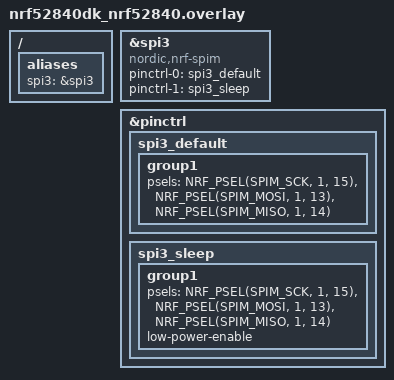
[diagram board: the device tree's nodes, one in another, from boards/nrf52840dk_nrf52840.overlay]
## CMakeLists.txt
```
cmake_minimum_required(VERSION 3.20.0)

find_package(Zephyr REQUIRED HINTS $ENV{ZEPHYR_BASE})
project(biospur_gr_module)

target_sources(app PRIVATE
  src/main.c
  src/ads1298.c
  src/device_id.c
)

target_include_directories(app PRIVATE
  ${CMAKE_CURRENT_SOURCE_DIR}/include
  ${CMAKE_CURRENT_SOURCE_DIR}/../shared/include
)
```

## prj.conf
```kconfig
# GR module: B306 / nRF52840 BLE Peripheral baseline.

CONFIG_MAIN_STACK_SIZE=4096
CONFIG_SYSTEM_WORKQUEUE_STACK_SIZE=2048
CONFIG_HEAP_MEM_POOL_SIZE=8192

CONFIG_PRINTK=y
CONFIG_CONSOLE=y
CONFIG_UART_CONSOLE=n
CONFIG_USE_SEGGER_RTT=y
CONFIG_RTT_CONSOLE=y

CONFIG_BT=y
CONFIG_BT_PERIPHERAL=y
CONFIG_BT_CENTRAL=n
CONFIG_BT_DEVICE_NAME_DYNAMIC=y
CONFIG_BT_MAX_CONN=1
CONFIG_BT_NUS=y
CONFIG_BT_GATT_CLIENT=y
CONFIG_BT_GATT_DM=y

CONFIG_BT_CTLR_PHY_2M=y
CONFIG_BT_USER_PHY_UPDATE=y
CONFIG_BT_CTLR_DATA_LENGTH_MAX=251
CONFIG_BT_L2CAP_TX_MTU=247
CONFIG_BT_BUF_ACL_TX_SIZE=251
CONFIG_BT_BUF_ACL_RX_SIZE=251
CONFIG_BT_BUF_ACL_TX_COUNT=10
CONFIG_BT_BUF_ACL_RX_COUNT=10
CONFIG_BT_CONN_TX_MAX=16

CONFIG_GPIO=y
CONFIG_PINCTRL=y
CONFIG_I2C=y
CONFIG_SPI=y

CONFIG_BOOTLOADER_MCUBOOT=y
CONFIG_MCUBOOT_BOOTUTIL_LIB=y
CONFIG_MCUBOOT_SIGNATURE_KEY_FILE="bootloader/mcuboot/root-ec-p256.pem"
CONFIG_MCUBOOT_IMGTOOL_SIGN_VERSION="0.0.3+0"
CONFIG_FLASH=y
CONFIG_FLASH_PAGE_LAYOUT=y
CONFIG_FLASH_MAP=y
CONFIG_IMG_MANAGER=y
CONFIG_STREAM_FLASH=y

CONFIG_NET_BUF=y
CONFIG_ZCBOR=y
CONFIG_CRC=y
CONFIG_MCUMGR=y
CONFIG_MCUMGR_GRP_IMG=y
CONFIG_MCUMGR_GRP_IMG_VERBOSE_ERR=y
CONFIG_MCUMGR_GRP_IMG_ALLOW_ERASE_PENDING=y
CONFIG_MCUMGR_GRP_OS=y
CONFIG_MCUMGR_GRP_OS_BOOTLOADER_INFO=y
CONFIG_MCUMGR_GRP_OS_MCUMGR_PARAMS=y
CONFIG_MCUMGR_TRANSPORT_BT=y
CONFIG_MCUMGR_TRANSPORT_BT_PERM_RW=y
CONFIG_MCUMGR_TRANSPORT_BT_CONN_PARAM_CONTROL=y
CONFIG_MCUMGR_TRANSPORT_BT_REASSEMBLY=y
CONFIG_MCUMGR_TRANSPORT_NETBUF_SIZE=1536
CONFIG_MCUMGR_TRANSPORT_WORKQUEUE_STACK_SIZE=3072
```

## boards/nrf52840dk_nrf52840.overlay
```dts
/ {
	aliases {
		spi3 = &spi3;
	};
};

&spi3 {
	compatible = "nordic,nrf-spim";
	status = "okay";
	pinctrl-0 = <&spi3_default>;
	pinctrl-1 = <&spi3_sleep>;
	pinctrl-names = "default", "sleep";
};

&pinctrl {
	spi3_default: spi3_default {
		group1 {
			psels = <NRF_PSEL(SPIM_SCK, 1, 15)>,
				<NRF_PSEL(SPIM_MOSI, 1, 13)>,
				<NRF_PSEL(SPIM_MISO, 1, 14)>;
		};
	};

	spi3_sleep: spi3_sleep {
		group1 {
			psels = <NRF_PSEL(SPIM_SCK, 1, 15)>,
				<NRF_PSEL(SPIM_MOSI, 1, 13)>,
				<NRF_PSEL(SPIM_MISO, 1, 14)>;
			low-power-enable;
		};
	};
};
```

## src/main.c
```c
#include "ads1298.h"
#include "app_config.h"
#include "device_id.h"
#include "gr_protocol.h"

#include <errno.h>
#include <stddef.h>
#include <stdint.h>
#include <string.h>

#include <zephyr/bluetooth/bluetooth.h>
#include <zephyr/bluetooth/conn.h>
#include <zephyr/bluetooth/gatt.h>
#include <zephyr/bluetooth/hci.h>
#include <zephyr/dfu/mcuboot.h>
#include <zephyr/kernel.h>
#include <zephyr/sys/byteorder.h>
#include <zephyr/sys/printk.h>

#include <bluetooth/services/nus.h>

static struct bt_conn *current_conn;
static struct k_mutex conn_mutex;
static uint16_t status_seq;
static uint16_t emg_seq;
static int64_t host_time_offset_ms;

struct emg_sample {
	uint8_t status[3];
	int32_t ch_code[8];
};

static struct emg_sample emg_samples[EMG_SAMPLES_PER_FRAME];
static uint8_t emg_sample_count;
static uint32_t emg_sent_count;
static uint32_t emg_drop_count;

static void confirm_running_image(void)
{
	int err = boot_write_img_confirmed();

	if (err == 0) {
		printk("GR MCUboot image confirmed\n");
	} else {
		printk("GR MCUboot confirm rc=%d\n", err);
	}
}

static uint32_t gr_now_host_ms(void)
{
	int64_t host_ms = (int64_t)k_uptime_get() + host_time_offset_ms;

	return (uint32_t)(host_ms < 0 ? 0 : host_ms);
}

static struct bt_conn *conn_ref_current(void)
{
	struct bt_conn *conn = NULL;

	k_mutex_lock(&conn_mutex, K_FOREVER);
	if (current_conn != NULL) {
		conn = bt_conn_ref(current_conn);
	}
	k_mutex_unlock(&conn_mutex);

	return conn;
}

static void send_status_once(void)
{
	struct bt_conn *conn = conn_ref_current();

	if (conn == NULL) {
		return;
	}

	uint8_t frame[sizeof(struct gr_packet_header) + 8];
	struct gr_packet_header *hdr = (struct gr_packet_header *)frame;
	uint8_t *payload = &frame[sizeof(*hdr)];

	hdr->magic = GR_PACKET_MAGIC;
	hdr->type = GR_TYPE_STATUS;
	sys_put_le16(status_seq++, (uint8_t *)&hdr->seq);
	sys_put_le16(device_id_get16(), (uint8_t *)&hdr->device_id);
	sys_put_le32(gr_now_host_ms(), (uint8_t *)&hdr->timestamp_ms);

	payload[0] = 'B';
	payload[1] = '3';
	payload[2] = '0';
	payload[3] = '6';
	sys_put_le32((uint32_t)k_uptime_get(), &payload[4]);

	int err = bt_nus_send(conn, frame, sizeof(frame));
	if (err) {
		printk("GR status send failed: %d\n", err);
	}
	bt_conn_unref(conn);
}

static uint16_t next_emg_seq(void)
{
	uint16_t seq = emg_seq;

	emg_seq = (uint16_t)(emg_seq + 1U);
	return seq;
}

static void emg_flush(uint8_t sample_count)
{
	struct bt_conn *conn;
	uint8_t frame[sizeof(struct gr_packet_header) + 4 +
		      (EMG_SAMPLES_PER_FRAME * (3 + 8 * 3))];
	struct gr_packet_header *hdr = (struct gr_packet_header *)frame;
	uint8_t *p = &frame[sizeof(*hdr)];
	size_t len;
	int err;

	if (sample_count == 0U) {
		return;
	}

	conn = conn_ref_current();
	if (conn == NULL) {
		emg_drop_count++;
		return;
	}

	hdr->magic = GR_PACKET_MAGIC;
	hdr->type = GR_TYPE_ADS1298;
	sys_put_le16(next_emg_seq(), (uint8_t *)&hdr->seq);
	sys_put_le16(device_id_get16(), (uint8_t *)&hdr->device_id);
	sys_put_le32(gr_now_host_ms(), (uint8_t *)&hdr->timestamp_ms);

	*p++ = sample_count;
	*p++ = 0xff;
	sys_put_le16(EMG_SAMPLE_RATE_SPS, p);
	p += 2;

	for (uint8_t s = 0; s < sample_count; s++) {
		memcpy(p, emg_samples[s].status, sizeof(emg_samples[s].status));
		p += sizeof(emg_samples[s].status);

		for (int ch = 0; ch < 8; ch++) {
			int32_t v = emg_samples[s].ch_code[ch];

			*p++ = (uint8_t)((v >> 16) & 0xff);
			*p++ = (uint8_t)((v >> 8) & 0xff);
			*p++ = (uint8_t)(v & 0xff);
		}
	}

	len = (size_t)(p - frame);
	err = bt_nus_send(conn, frame, len);
	if (err) {
		emg_drop_count++;
		if ((emg_drop_count % 100U) == 1U) {
			printk("GR EMG send failed: %d drops=%u\n",
			       err, (unsigned int)emg_drop_count);
		}
	} else {
		emg_sent_count++;
	}

	bt_conn_unref(conn);
}

static void ads_frame_received(const int32_t ch_code[8], const uint8_t status[3])
{
	struct emg_sample *sample;

	if (emg_sample_count >= EMG_SAMPLES_PER_FRAME) {
		emg_sample_count = 0;
	}

	sample = &emg_samples[emg_sample_count++];
	memcpy(sample->status, status, sizeof(sample->status));
	for (int i = 0; i < 8; i++) {
		sample->ch_code[i] = ch_code[i];
	}

	if (emg_sample_count >= EMG_SAMPLES_PER_FRAME) {
		emg_flush(emg_sample_count);
		emg_sample_count = 0;
	}
}

static void nus_received(struct bt_conn *conn, const uint8_t *data, uint16_t len)
{
	ARG_UNUSED(conn);

	if (len == 10U && data[0] == GR_PACKET_MAGIC && data[1] == GR_TYPE_TSYNC) {
		uint64_t host_ms = sys_get_le64(&data[2]);
		host_time_offset_ms = (int64_t)host_ms - (int64_t)k_uptime_get();
		printk("GR TSYNC offset=%lld\n", (long long)host_time_offset_ms);
		return;
	}

	if ((len >= 11U && memcmp(data, "OTA_PREPARE", 11) == 0) ||
	    (len >= 13U && data[0] == GR_PACKET_MAGIC && data[1] == GR_TYPE_COMMAND &&
	     memcmp(&data[2], "OTA_PREPARE", 11) == 0)) {
		printk("GR OTA_PREPARE received\n");
		return;
	}

	printk("GR command len=%u type=0x%02x\n", len, len > 1 ? data[1] : 0);
}

static struct bt_nus_cb nus_cb = {
	.received = nus_received,
};

static void connected(struct bt_conn *conn, uint8_t err)
{
	if (err) {
		printk("GR connection failed: 0x%02x\n", err);
		return;
	}

	k_mutex_lock(&conn_mutex, K_FOREVER);
	if (current_conn != NULL) {
		bt_conn_unref(current_conn);
	}
	current_conn = bt_conn_ref(conn);
	k_mutex_unlock(&conn_mutex);
	printk("GR connected\n");
}

static void disconnected(struct bt_conn *conn, uint8_t reason)
{
	ARG_UNUSED(conn);

	printk("GR disconnected: 0x%02x\n", reason);

	k_mutex_lock(&conn_mutex, K_FOREVER);
	if (current_conn != NULL) {
		bt_conn_unref(current_conn);
		current_conn = NULL;
	}
	k_mutex_unlock(&conn_mutex);
}

BT_CONN_CB_DEFINE(conn_callbacks) = {
	.connected = connected,
	.disconnected = disconnected,
};

static int start_advertising(void)
{
	const char *name = device_bt_name_get();
	uint8_t mfg[] = {
		0xff, 0xff,
		GR_ADV_MFG_MAGIC0,
		GR_ADV_MFG_MAGIC1,
		GR_ADV_MFG_VERSION,
		0x00,
		(uint8_t)(device_id_get16() & 0xffU),
		(uint8_t)(device_id_get16() >> 8),
	};

	const struct bt_data ad[] = {
		BT_DATA_BYTES(BT_DATA_FLAGS, BT_LE_AD_GENERAL | BT_LE_AD_NO_BREDR),
		BT_DATA(BT_DATA_NAME_COMPLETE, name, strlen(name)),
		BT_DATA(BT_DATA_MANUFACTURER_DATA, mfg, sizeof(mfg)),
	};
	const struct bt_data sd[] = {
		BT_DATA_BYTES(BT_DATA_UUID128_ALL,
			      0x84, 0xaa, 0x60, 0x74, 0x52, 0x8a, 0x8b, 0x86,
			      0xd3, 0x4c, 0xb7, 0x1d, 0x1d, 0xdc, 0x53, 0x8d),
	};

	return bt_le_adv_start(BT_LE_ADV_CONN, ad, ARRAY_SIZE(ad), sd, ARRAY_SIZE(sd));
}

int main(void)
{
	device_id_init();
	k_mutex_init(&conn_mutex);
	confirm_running_image();

	int err = bt_enable(NULL);
	if (err) {
		printk("GR bt_enable failed: %d\n", err);
		return err;
	}

	err = bt_nus_init(&nus_cb);
	if (err) {
		printk("GR bt_nus_init failed: %d\n", err);
		return err;
	}

	bt_set_name(device_bt_name_get());

	err = start_advertising();
	printk("GR module ready name=%s adv=%d\n", device_bt_name_get(), err);

	err = ads1298_init();
	if (err) {
		printk("GR ADS1298 init failed: %d\n", err);
	} else {
		ads1298_set_frame_callback(ads_frame_received);
		ads1298_start();
	}

	while (1) {
		send_status_once();
		k_sleep(K_SECONDS(1));
	}
}
```

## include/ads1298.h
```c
#pragma once

#include <stdint.h>

typedef void (*ads1298_frame_cb_t)(const int32_t ch_code[8],
				   const uint8_t status[3]);

int ads1298_init(void);
void ads1298_start(void);
void ads1298_set_frame_callback(ads1298_frame_cb_t cb);
```

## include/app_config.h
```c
#pragma once

#include <zephyr/kernel.h>

#define EMG_STACK_SIZE 2048
#define EMG_PRIO 4

#define EMG_SAMPLE_RATE_SPS 1000
#define EMG_SAMPLES_PER_FRAME 4

#if (EMG_SAMPLE_RATE_SPS != 250)  && \
    (EMG_SAMPLE_RATE_SPS != 500)  && \
    (EMG_SAMPLE_RATE_SPS != 1000) && \
    (EMG_SAMPLE_RATE_SPS != 2000) && \
    (EMG_SAMPLE_RATE_SPS != 4000)
#error "EMG_SAMPLE_RATE_SPS must be one of: 250/500/1000/2000/4000"
#endif

#if (EMG_SAMPLES_PER_FRAME < 1) || (EMG_SAMPLES_PER_FRAME > 4)
#error "EMG_SAMPLES_PER_FRAME must be 1..4"
#endif
```

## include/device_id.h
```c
#pragma once

#include <stdint.h>

void device_id_init(void);
uint16_t device_id_get16(void);
const char *device_bt_name_get(void);
```

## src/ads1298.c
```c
#include "ads1298.h"
#include "app_config.h"

#include <errno.h>
#include <limits.h>
#include <stdint.h>
#include <string.h>

#include <zephyr/device.h>
#include <zephyr/devicetree.h>
#include <zephyr/drivers/gpio.h>
#include <zephyr/drivers/spi.h>
#include <zephyr/kernel.h>
#include <zephyr/sys/atomic.h>
#include <zephyr/sys/printk.h>
#include <zephyr/sys/util.h>

#define SPI_HZ 1000000U
#define DRDY_TIMEOUT_MS 20
#define PREFILL_DROP_FRAMES 10
#define CS_GUARD_US 10

#define ADS_DEBUG_EVERY_N_FRAMES 500U
#define ADS_SELF_TEST_ENABLE 0
#define ADS_SELF_TEST_FRAMES 64
#define ADS_SELF_TEST_SKIP 4

#if (EMG_SAMPLE_RATE_SPS == 4000)
#define CONFIG1_VALUE 0x83
#elif (EMG_SAMPLE_RATE_SPS == 2000)
#define CONFIG1_VALUE 0x84
#elif (EMG_SAMPLE_RATE_SPS == 1000)
#define CONFIG1_VALUE 0x85
#elif (EMG_SAMPLE_RATE_SPS == 500)
#define CONFIG1_VALUE 0x86
#elif (EMG_SAMPLE_RATE_SPS == 250)
#define CONFIG1_VALUE 0x87
#else
#error "Unsupported EMG_SAMPLE_RATE_SPS for ADS1298"
#endif

#define CONFIG2_VALUE 0x40
#define CONFIG3_VALUE 0x8C
#define RLD_SENSP_VALUE 0xFF
#define RLD_SENSN_VALUE 0xFF

#define PIN_CS 12
#define PIN_RESET 11
#define PIN_DRDY 8
#define PIN_START 1

#define SPI_NODE DT_NODELABEL(spi3)
#define GPIO1_NODE DT_NODELABEL(gpio1)

static const struct device *const spi_dev = DEVICE_DT_GET(SPI_NODE);
static const struct device *const gpio1 = DEVICE_DT_GET(GPIO1_NODE);

static const spi_operation_t spi_base_op =
	SPI_OP_MODE_MASTER | SPI_WORD_SET(8) | SPI_TRANSFER_MSB;

static struct spi_config spi_cfg = {
	.frequency = SPI_HZ,
	.operation = SPI_OP_MODE_MASTER | SPI_WORD_SET(8) |
		     SPI_TRANSFER_MSB | SPI_MODE_CPHA,
	.slave = 0,
	.cs = { .gpio = { 0 }, .delay = 0 },
};

enum {
	CMD_RESET_CMD = 0x06,
	CMD_RDATAC = 0x10,
	CMD_SDATAC = 0x11,
	CMD_RREG = 0x20,
	CMD_WREG = 0x40,
};

#define REG_ID 0x00
#define REG_CONFIG1 0x01
#define REG_CONFIG2 0x02
#define REG_CONFIG3 0x03
#define REG_CH1SET 0x05
#define REG_RLD_SENSP 0x0D
#define REG_RLD_SENSN 0x0E

#define CH_GAIN_12 (0x03 << 4)
#define CH_MUX_NORMAL 0x00
#define CH_MUX_TEST 0x05

static struct k_sem drdy_sem;
static struct gpio_callback drdy_cb;
static atomic_t drdy_count = ATOMIC_INIT(0);
static ads1298_frame_cb_t frame_cb;

static inline void cs_low(void)
{
	gpio_pin_set(gpio1, PIN_CS, 0);
}

static inline void cs_high(void)
{
	gpio_pin_set(gpio1, PIN_CS, 1);
}

static int spi_write_1(const uint8_t *buf, size_t len)
{
	struct spi_buf txb = { .buf = (void *)buf, .len = len };
	struct spi_buf_set tx = { .buffers = &txb, .count = 1 };
	int ret;

	cs_low();
	k_busy_wait(CS_GUARD_US);
	ret = spi_write(spi_dev, &spi_cfg, &tx);
	k_busy_wait(CS_GUARD_US);
	cs_high();

	return ret;
}

static int spi_trx(const uint8_t *txbuf, uint8_t *rxbuf, size_t n)
{
	struct spi_buf txb = { .buf = (void *)txbuf, .len = n };
	struct spi_buf rxb = { .buf = rxbuf, .len = n };
	struct spi_buf_set txs = { .buffers = &txb, .count = 1 };
	struct spi_buf_set rxs = { .buffers = &rxb, .count = 1 };
	int ret;

	cs_low();
	k_busy_wait(CS_GUARD_US);
	ret = spi_transceive(spi_dev, &spi_cfg, &txs, &rxs);
	k_busy_wait(CS_GUARD_US);
	cs_high();

	return ret;
}

static int ads_cmd(uint8_t cmd)
{
	return spi_write_1(&cmd, 1);
}

static inline void ads_tdecode_gap(void)
{
	k_busy_wait(5);
}

static int ads_rreg(uint8_t addr, uint8_t *out, size_t n)
{
	uint8_t op1 = (uint8_t)(CMD_RREG | (addr & 0x1F));
	uint8_t op2 = (uint8_t)(n - 1U);
	uint8_t zero[32] = { 0 };

	if (n == 0U || n > sizeof(zero)) {
		return -EINVAL;
	}

	cs_low();
	k_busy_wait(CS_GUARD_US);

	if (spi_write(spi_dev, &spi_cfg,
		      &(struct spi_buf_set){
			      .buffers = (struct spi_buf[]){ { &op1, 1 } },
			      .count = 1 }) != 0) {
		goto out_err;
	}
	ads_tdecode_gap();
	if (spi_write(spi_dev, &spi_cfg,
		      &(struct spi_buf_set){
			      .buffers = (struct spi_buf[]){ { &op2, 1 } },
			      .count = 1 }) != 0) {
		goto out_err;
	}
	ads_tdecode_gap();
	if (spi_transceive(spi_dev, &spi_cfg,
			   &(struct spi_buf_set){
				   .buffers = (struct spi_buf[]){ { zero, n } },
				   .count = 1 },
			   &(struct spi_buf_set){
				   .buffers = (struct spi_buf[]){ { out, n } },
				   .count = 1 }) != 0) {
		goto out_err;
	}

	k_busy_wait(CS_GUARD_US);
	cs_high();
	return 0;

out_err:
	k_busy_wait(CS_GUARD_US);
	cs_high();
	return -EIO;
}

static int ads_wreg_slow(uint8_t addr, const uint8_t *in, size_t n)
{
	uint32_t old_hz = spi_cfg.frequency;
	uint8_t op1 = (uint8_t)(CMD_WREG | (addr & 0x1F));
	uint8_t op2 = (uint8_t)(n - 1U);
	int ok = -EIO;

	if (n == 0U || n > 32U) {
		return -EINVAL;
	}

	spi_cfg.frequency = 1000000U;

	for (int attempt = 0; attempt < 3 && ok != 0; ++attempt) {
		cs_low();
		k_busy_wait(CS_GUARD_US);

		if (spi_write(spi_dev, &spi_cfg,
			      &(struct spi_buf_set){
				      .buffers = (struct spi_buf[]){ { &op1, 1 } },
				      .count = 1 }) != 0) {
			goto done;
		}
		ads_tdecode_gap();
		if (spi_write(spi_dev, &spi_cfg,
			      &(struct spi_buf_set){
				      .buffers = (struct spi_buf[]){ { &op2, 1 } },
				      .count = 1 }) != 0) {
			goto done;
		}
		ads_tdecode_gap();
		if (spi_write(spi_dev, &spi_cfg,
			      &(struct spi_buf_set){
				      .buffers = (struct spi_buf[]){
					      { (void *)in, n } },
				      .count = 1 }) != 0) {
			goto done;
		}

		k_busy_wait(CS_GUARD_US);
		cs_high();

		if (n == 1U) {
			uint8_t rd = 0;

			if (ads_rreg(addr, &rd, 1) == 0 && rd == in[0]) {
				ok = 0;
				break;
			}
			printk("ADS1298 WREG verify fail addr=0x%02x want=0x%02x retry=%d\n",
			       addr, in[0], attempt + 1);
			k_busy_wait(50);
		} else {
			ok = 0;
		}
		continue;

done:
		k_busy_wait(CS_GUARD_US);
		cs_high();
		ok = -EIO;
	}

	spi_cfg.frequency = old_hz;
	return ok;
}

static int ads_reset_and_idle(void)
{
	gpio_pin_set(gpio1, PIN_RESET, 0);
	k_msleep(2);
	gpio_pin_set(gpio1, PIN_RESET, 1);
	k_msleep(5);

	gpio_pin_set(gpio1, PIN_START, 0);

	ads_cmd(CMD_RESET_CMD);
	k_sleep(K_USEC(200));
	ads_cmd(CMD_SDATAC);
	k_sleep(K_USEC(10));

	return 0;
}

static void ads_read_id_debug(void)
{
	uint32_t old_hz = spi_cfg.frequency;
	spi_operation_t old_op = spi_cfg.operation;
	const uint32_t speeds[] = { 100000U, 500000U, 1000000U };
	const spi_operation_t modes[] = {
		0,
		SPI_MODE_CPHA,
		SPI_MODE_CPOL,
		SPI_MODE_CPOL | SPI_MODE_CPHA,
	};
	bool found = false;

	k_msleep(2);
	for (int m = 0; m < ARRAY_SIZE(modes); m++) {
		spi_cfg.operation = spi_base_op | modes[m];
		for (size_t s = 0; s < ARRAY_SIZE(speeds); s++) {
			spi_cfg.frequency = speeds[s];
			k_msleep(2);

			uint8_t tx[3] = {
				(uint8_t)(CMD_RREG | (REG_ID & 0x1F)),
				0x00,
				0x00,
			};
			uint8_t rx[3] = { 0 };

			if (spi_trx(tx, rx, sizeof(tx)) == 0) {
				uint8_t id = rx[2];

				printk("ADS1298 ID scan m=%d hz=%u id=0x%02x\n",
				       m, (unsigned int)spi_cfg.frequency, id);
				if (id != 0x00 && id != 0xFF) {
					found = true;
				}
			}
		}
	}

	if (!found) {
		printk("ADS1298 ID scan: no valid response\n");
	}

	spi_cfg.frequency = old_hz;
	spi_cfg.operation = old_op;
}

static int ads_config_all8_true_diff(void)
{
	const uint8_t c1 = CONFIG1_VALUE;
	const uint8_t c2 = CONFIG2_VALUE;
	const uint8_t c3 = CONFIG3_VALUE;
	const uint8_t rldp = RLD_SENSP_VALUE;
	const uint8_t rldn = RLD_SENSN_VALUE;
	uint8_t chs[8];
	uint8_t rd[8] = { 0 };

	for (int i = 0; i < ARRAY_SIZE(chs); i++) {
		chs[i] = (uint8_t)(CH_MUX_NORMAL | CH_GAIN_12);
	}

	if (ads_wreg_slow(REG_CONFIG1, &c1, 1) ||
	    ads_wreg_slow(REG_CONFIG2, &c2, 1) ||
	    ads_wreg_slow(REG_CONFIG3, &c3, 1) ||
	    ads_wreg_slow(REG_CH1SET, chs, sizeof(chs)) ||
	    ads_wreg_slow(REG_RLD_SENSP, &rldp, 1) ||
	    ads_wreg_slow(REG_RLD_SENSN, &rldn, 1)) {
		return -EIO;
	}

	k_msleep(5);

	(void)ads_rreg(REG_CH1SET, rd, sizeof(rd));
	printk("ADS1298 CH1..8: %02x %02x %02x %02x %02x %02x %02x %02x\n",
	       rd[0], rd[1], rd[2], rd[3], rd[4], rd[5], rd[6], rd[7]);
	return 0;
}

static int ads_set_all_channels(uint8_t ch_val)
{
	uint8_t chs[8];

	memset(chs, ch_val, sizeof(chs));
	return ads_wreg_slow(REG_CH1SET, chs, sizeof(chs));
}

static int ads_start_rdatac(void)
{
	ads_cmd(CMD_SDATAC);
	k_sleep(K_USEC(10));
	gpio_pin_set(gpio1, PIN_START, 1);
	k_sleep(K_USEC(10));
	ads_cmd(CMD_RDATAC);
	k_sleep(K_USEC(10));

	return 0;
}

static int ads_read_frame_27b(int32_t out_ch[8], uint8_t status[3])
{
	uint8_t tx_dummy[27] = { 0 };
	uint8_t rx[27] = { 0 };
	int ret = spi_trx(tx_dummy, rx, sizeof(rx));

	if (ret != 0) {
		printk("ADS1298 SPI xfer err=%d\n", ret);
		return ret;
	}

	status[0] = rx[0];
	status[1] = rx[1];
	status[2] = rx[2];

	for (int i = 0; i < 8; ++i) {
		int32_t v = ((int32_t)rx[3 + i * 3] << 16) |
			    ((int32_t)rx[4 + i * 3] << 8) |
			    (int32_t)rx[5 + i * 3];

		if ((v & 0x00800000) != 0) {
			v |= 0xFF000000;
		}
		out_ch[i] = v;
	}

	return 0;
}

static int ads_self_test(void)
{
	int32_t minv[8];
	int32_t maxv[8];
	int32_t ch_code[8];
	uint8_t status[3];
	uint8_t c2_test = (uint8_t)(CONFIG2_VALUE | 0x80);
	uint8_t c2_norm = CONFIG2_VALUE;
	int ret;

	for (int i = 0; i < ARRAY_SIZE(minv); i++) {
		minv[i] = INT32_MAX;
		maxv[i] = INT32_MIN;
	}

	printk("ADS1298 self-test: enable internal test signal\n");
	ads_cmd(CMD_SDATAC);
	k_sleep(K_USEC(10));
	gpio_pin_set(gpio1, PIN_START, 0);
	k_msleep(1);

	ret = ads_wreg_slow(REG_CONFIG2, &c2_test, 1);
	if (ret != 0) {
		goto restore;
	}
	ret = ads_set_all_channels((uint8_t)(CH_MUX_TEST | CH_GAIN_12));
	if (ret != 0) {
		goto restore;
	}

	gpio_pin_set(gpio1, PIN_START, 1);
	k_sleep(K_USEC(10));
	ads_cmd(CMD_RDATAC);
	k_sleep(K_USEC(10));

	for (int i = 0; i < ADS_SELF_TEST_SKIP + ADS_SELF_TEST_FRAMES;) {
		if (k_sem_take(&drdy_sem, K_MSEC(DRDY_TIMEOUT_MS)) != 0) {
			continue;
		}
		if (ads_read_frame_27b(ch_code, status) != 0) {
			continue;
		}

		if (i >= ADS_SELF_TEST_SKIP) {
			for (int ch = 0; ch < 8; ch++) {
				minv[ch] = MIN(minv[ch], ch_code[ch]);
				maxv[ch] = MAX(maxv[ch], ch_code[ch]);
			}
		}
		i++;
	}

	printk("ADS1298 self-test CH1=%d..%d CH8=%d..%d\n",
	       minv[0], maxv[0], minv[7], maxv[7]);

restore:
	ads_cmd(CMD_SDATAC);
	k_sleep(K_USEC(10));
	gpio_pin_set(gpio1, PIN_START, 0);
	k_msleep(1);
	(void)ads_wreg_slow(REG_CONFIG2, &c2_norm, 1);
	(void)ads_set_all_channels((uint8_t)(CH_MUX_NORMAL | CH_GAIN_12));
	return ret;
}

static void drdy_isr(const struct device *dev, struct gpio_callback *cb,
		     uint32_t pins)
{
	ARG_UNUSED(dev);
	ARG_UNUSED(cb);
	ARG_UNUSED(pins);

	atomic_inc(&drdy_count);
	k_sem_give(&drdy_sem);
}

void ads1298_set_frame_callback(ads1298_frame_cb_t cb)
{
	frame_cb = cb;
}

static struct k_thread ads_thread;
K_THREAD_STACK_DEFINE(ads_stack, EMG_STACK_SIZE);

static void ads_sampling_thread(void *a, void *b, void *c)
{
	int32_t ch_code[8];
	uint8_t status[3];
	int64_t last_ok_ms = k_uptime_get();
	uint32_t dbg_cnt = 0;

	ARG_UNUSED(a);
	ARG_UNUSED(b);
	ARG_UNUSED(c);

	while (1) {
		if (k_sem_take(&drdy_sem, K_MSEC(DRDY_TIMEOUT_MS)) != 0) {
			printk("ADS1298 missed frame\n");
			if (k_uptime_get() - last_ok_ms > 2000) {
				ads_cmd(CMD_SDATAC);
				k_msleep(2);
				ads_cmd(CMD_RDATAC);
				k_msleep(2);
				last_ok_ms = k_uptime_get();
			}
			continue;
		}

		if (ads_read_frame_27b(ch_code, status) != 0) {
			continue;
		}
		last_ok_ms = k_uptime_get();

		if (frame_cb != NULL) {
			frame_cb(ch_code, status);
		}

		if ((dbg_cnt++ % ADS_DEBUG_EVERY_N_FRAMES) == 0U) {
			printk("ADS1298 STS:%02x %02x %02x CH1=%08x CH8=%08x\n",
			       status[0], status[1], status[2],
			       (unsigned int)ch_code[0],
			       (unsigned int)ch_code[7]);
		}
	}
}

int ads1298_init(void)
{
	if (!device_is_ready(spi_dev) || !device_is_ready(gpio1)) {
		printk("ADS1298 spi3/gpio1 not ready\n");
		return -ENODEV;
	}

	gpio_pin_configure(gpio1, PIN_CS, GPIO_OUTPUT_HIGH);
	gpio_pin_configure(gpio1, PIN_RESET, GPIO_OUTPUT_HIGH);
	gpio_pin_configure(gpio1, PIN_START, GPIO_OUTPUT_INACTIVE);
	gpio_pin_configure(gpio1, PIN_DRDY, GPIO_INPUT | GPIO_PULL_UP);

	k_sem_init(&drdy_sem, 0, 32);
	gpio_pin_interrupt_configure(gpio1, PIN_DRDY, GPIO_INT_EDGE_FALLING);
	gpio_init_callback(&drdy_cb, drdy_isr, BIT(PIN_DRDY));
	gpio_add_callback(gpio1, &drdy_cb);

	ads_reset_and_idle();
	ads_read_id_debug();

	if (ads_config_all8_true_diff() != 0) {
		printk("ADS1298 WREG failed\n");
		return -EIO;
	}

#if ADS_SELF_TEST_ENABLE
	(void)ads_self_test();
#else
	ARG_UNUSED(ads_self_test);
#endif

	ads_start_rdatac();

	k_msleep(200);
	while (k_sem_take(&drdy_sem, K_NO_WAIT) == 0) {
	}

	for (int i = 0; i < PREFILL_DROP_FRAMES;) {
		int32_t tmp[8];
		uint8_t st[3];

		if (k_sem_take(&drdy_sem, K_MSEC(DRDY_TIMEOUT_MS)) == 0 &&
		    ads_read_frame_27b(tmp, st) == 0) {
			i++;
		}
	}

	printk("ADS1298 capture ready rate=%u sps samples_per_ble_frame=%u\n",
	       EMG_SAMPLE_RATE_SPS, EMG_SAMPLES_PER_FRAME);
	return 0;
}

void ads1298_start(void)
{
	k_thread_create(&ads_thread, ads_stack, K_THREAD_STACK_SIZEOF(ads_stack),
			ads_sampling_thread, NULL, NULL, NULL,
			EMG_PRIO, 0, K_NO_WAIT);
	k_thread_name_set(&ads_thread, "ads1298");
}
```

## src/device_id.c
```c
#include "device_id.h"

#include <zephyr/kernel.h>
#include <zephyr/sys/sys_io.h>
#include <zephyr/sys/printk.h>

static char bt_name[8];
static uint16_t dev_id16;

void device_id_init(void)
{
	uint32_t id0 = sys_read32(0x10000060);
	uint8_t b0 = (uint8_t)(id0 & 0xffU);
	uint8_t b1 = (uint8_t)((id0 >> 8) & 0xffU);

	dev_id16 = ((uint16_t)b1 << 8) | b0;
	snprintk(bt_name, sizeof(bt_name), "GR%02X%02X", b0, b1);
}

uint16_t device_id_get16(void)
{
	return dev_id16;
}

const char *device_bt_name_get(void)
{
	return bt_name;
}
```
